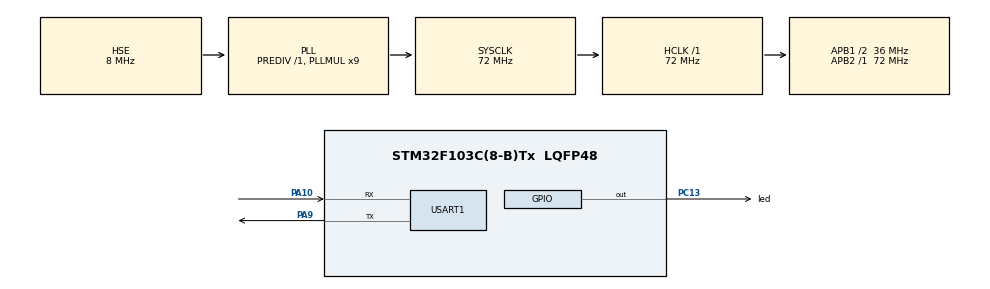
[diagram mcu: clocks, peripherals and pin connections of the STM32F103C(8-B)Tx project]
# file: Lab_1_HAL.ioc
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FREERTOS.Tasks01=defaultTask,0,128,StartDefaultTask,Default,NULL,Dynamic,NULL,NULL;myLedTask,0,128,StartLedTask,Default,NULL,Dynamic,NULL,NULL;myUartTask,0,128,StartUartTask,Default,NULL,Dynamic,NULL,NULL
Mcu.Family=STM32F1
Mcu.Name=STM32F103C(8-B)Tx
Mcu.Package=LQFP48
NVIC.PriorityGroup=NVIC_PRIORITYGROUP_4
NVIC.TIM3_IRQn=true\:0\:0\:false\:false\:true\:false\:false\:true
NVIC.TimeBase=TIM3_IRQn
NVIC.TimeBaseIP=TIM3
PA10.Mode=Asynchronous
PA10.Signal=USART1_RX
PA13.Mode=Serial_Wire
PA13.Signal=SYS_JTMS-SWDIO
PA14.Mode=Serial_Wire
PA14.Signal=SYS_JTCK-SWCLK
PA9.Mode=Asynchronous
PA9.Signal=USART1_TX
PC13-TAMPER-RTC.GPIO_Label=led
PC13-TAMPER-RTC.Signal=GPIO_Output
PD0-OSC_IN.Mode=HSE-External-Oscillator
PD0-OSC_IN.Signal=RCC_OSC_IN
PD1-OSC_OUT.Mode=HSE-External-Oscillator
PD1-OSC_OUT.Signal=RCC_OSC_OUT
ProjectManager.HeapSize=0x200
ProjectManager.StackSize=0x400
ProjectManager.TargetToolchain=STM32CubeIDE
RCC.AHBFreq_Value=72000000
RCC.APB1CLKDivider=RCC_HCLK_DIV2
RCC.APB1Freq_Value=36000000
RCC.APB1TimFreq_Value=72000000
RCC.APB2Freq_Value=72000000
RCC.APB2TimFreq_Value=72000000
RCC.HCLKFreq_Value=72000000
RCC.PLLMUL=RCC_PLL_MUL9
RCC.PLLSourceVirtual=RCC_PLLSOURCE_HSE
RCC.SYSCLKFreq_VALUE=72000000
RCC.SYSCLKSource=RCC_SYSCLKSOURCE_PLLCLK
RCC.USBFreq_Value=72000000
USART1.VirtualMode=VM_ASYNC
VP_FREERTOS_VS_CMSIS_V1.Mode=CMSIS_V1
VP_SYS_VS_tim3.Mode=TIM3
board=custom

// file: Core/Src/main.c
/* USER CODE BEGIN Header */
/**
  ******************************************************************************
  * @file           : main.c
  * @brief          : Main program body
  ******************************************************************************
  * @attention
  *
  * <h2><center>&copy; Copyright (c) 2020 STMicroelectronics.
  * All rights reserved.</center></h2>
  *
  * This software component is licensed by ST under Ultimate Liberty license
  * SLA0044, the "License"; You may not use this file except in compliance with
  * the License. You may obtain a copy of the License at:
  *                             www.st.com/SLA0044
  *
  ******************************************************************************
  */
/* USER CODE END Header */
#include "main.h"
#include "cmsis_os.h"

UART_HandleTypeDef huart1;

osThreadId defaultTaskHandle;
osThreadId myLedTaskHandle;
osThreadId myUartTaskHandle;

void SystemClock_Config(void);
static void MX_GPIO_Init(void);
static void MX_USART1_UART_Init(void);
void StartDefaultTask(void const * argument);
void StartLedTask(void const * argument);
void StartUartTask(void const * argument);

int main(void)
{

  /* MCU Configuration--------------------------------------------------------*/

  /* Reset of all peripherals, Initializes the Flash interface and the Systick. */
  HAL_Init();

  /* Configure the system clock */
  SystemClock_Config();

  /* Initialize all configured peripherals */
  MX_GPIO_Init();
  MX_USART1_UART_Init();

  /* Create the thread(s) */
  /* definition and creation of defaultTask */
  osThreadDef(defaultTask, StartDefaultTask, osPriorityNormal, 0, 128);
  defaultTaskHandle = osThreadCreate(osThread(defaultTask), NULL);

  /* definition and creation of myLedTask */
  osThreadDef(myLedTask, StartLedTask, osPriorityNormal, 0, 128);
  myLedTaskHandle = osThreadCreate(osThread(myLedTask), NULL);

  /* definition and creation of myUartTask */
  osThreadDef(myUartTask, StartUartTask, osPriorityNormal, 0, 128);
  myUartTaskHandle = osThreadCreate(osThread(myUartTask), NULL);

  /* Start scheduler */
  osKernelStart();

  /* We should never get here as control is now taken by the scheduler */
  /* Infinite loop */
  while (1)
  {

  }
}

void SystemClock_Config(void)
{
  RCC_OscInitTypeDef RCC_OscInitStruct = {0};
  RCC_ClkInitTypeDef RCC_ClkInitStruct = {0};

  /** Initializes the RCC Oscillators according to the specified parameters
  * in the RCC_OscInitTypeDef structure.
  */
  RCC_OscInitStruct.OscillatorType = RCC_OSCILLATORTYPE_HSE;
  RCC_OscInitStruct.HSEState = RCC_HSE_ON;
  RCC_OscInitStruct.HSEPredivValue = RCC_HSE_PREDIV_DIV1;
  RCC_OscInitStruct.HSIState = RCC_HSI_ON;
  RCC_OscInitStruct.PLL.PLLState = RCC_PLL_ON;
  RCC_OscInitStruct.PLL.PLLSource = RCC_PLLSOURCE_HSE;
  RCC_OscInitStruct.PLL.PLLMUL = RCC_PLL_MUL9;
  if (HAL_RCC_OscConfig(&RCC_OscInitStruct) != HAL_OK)
  {
    Error_Handler();
  }
  /** Initializes the CPU, AHB and APB buses clocks
  */
  RCC_ClkInitStruct.ClockType = RCC_CLOCKTYPE_HCLK|RCC_CLOCKTYPE_SYSCLK
                              |RCC_CLOCKTYPE_PCLK1|RCC_CLOCKTYPE_PCLK2;
  RCC_ClkInitStruct.SYSCLKSource = RCC_SYSCLKSOURCE_PLLCLK;
  RCC_ClkInitStruct.AHBCLKDivider = RCC_SYSCLK_DIV1;
  RCC_ClkInitStruct.APB1CLKDivider = RCC_HCLK_DIV2;
  RCC_ClkInitStruct.APB2CLKDivider = RCC_HCLK_DIV1;

  if (HAL_RCC_ClockConfig(&RCC_ClkInitStruct, FLASH_LATENCY_2) != HAL_OK)
  {
    Error_Handler();
  }
}

static void MX_USART1_UART_Init(void)
{

  huart1.Instance = USART1;
  huart1.Init.BaudRate = 115200;
  huart1.Init.WordLength = UART_WORDLENGTH_8B;
  huart1.Init.StopBits = UART_STOPBITS_1;
  huart1.Init.Parity = UART_PARITY_NONE;
  huart1.Init.Mode = UART_MODE_TX_RX;
  huart1.Init.HwFlowCtl = UART_HWCONTROL_NONE;
  huart1.Init.OverSampling = UART_OVERSAMPLING_16;
  if (HAL_UART_Init(&huart1) != HAL_OK)
  {
    Error_Handler();
  }

}

static void MX_GPIO_Init(void)
{
  GPIO_InitTypeDef GPIO_InitStruct = {0};

  /* GPIO Ports Clock Enable */
  __HAL_RCC_GPIOC_CLK_ENABLE();
  __HAL_RCC_GPIOD_CLK_ENABLE();
  __HAL_RCC_GPIOA_CLK_ENABLE();

  /*Configure GPIO pin Output Level */
  HAL_GPIO_WritePin(led_GPIO_Port, led_Pin, GPIO_PIN_RESET);

  /*Configure GPIO pin : led_Pin */
  GPIO_InitStruct.Pin = led_Pin;
  GPIO_InitStruct.Mode = GPIO_MODE_OUTPUT_PP;
  GPIO_InitStruct.Pull = GPIO_NOPULL;
  GPIO_InitStruct.Speed = GPIO_SPEED_FREQ_LOW;
  HAL_GPIO_Init(led_GPIO_Port, &GPIO_InitStruct);

}

void StartDefaultTask(void const * argument)
{
  for(;;)
  {
    osDelay(1);
  }
}

void StartLedTask(void const * argument)
{
  /* USER CODE BEGIN StartLedTask */
  /* Infinite loop */
  for(;;)
  {
		HAL_GPIO_TogglePin(led_GPIO_Port, led_Pin);
	    osDelay(100);
  }
  /* USER CODE END StartLedTask */
}

void StartUartTask(void const * argument)
{
  /* USER CODE BEGIN StartUartTask */
	uint8_t aTxBuff[10] = "Tick";

  /* Infinite loop */
  for(;;)
  {
	HAL_UART_Transmit(&huart1, (uint8_t*)aTxBuff, 10, 100);
    osDelay(100);
  }
  /* USER CODE END StartUartTask */
}

void HAL_TIM_PeriodElapsedCallback(TIM_HandleTypeDef *htim)
{
  if (htim->Instance == TIM3) {
    HAL_IncTick();
  }
}

void Error_Handler(void)
{
}

/************************ (C) COPYRIGHT STMicroelectronics *****END OF FILE****/
